# DEBUGSS_WRAP_SECAP_CFG_1_000740002600h register map
Vendor: Texas Instruments
Peripheral module from a debugger description file (folder am62D).
Registers are 32-bit, read-write, reset 0x0 unless marked. A register's access mark holds for its fields unless they carry their own. Offsets are as the file gives them; lines under a group give offsets from that group; [hi:lo] are bit positions; {n}, {i} and the like mark numbered series; 'fields as' and 'values as' point back to an identical list; <NAME> marks a mode.

## secap_cfg_1
0x00 secap_cfg_1_TXDATA — Data value to send to security controller. Apllication specific
  [31:0] TX_DATA_REGISTER
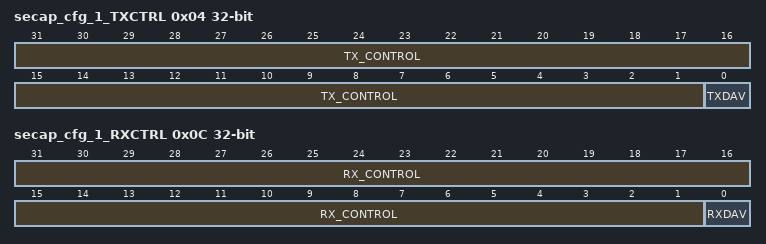
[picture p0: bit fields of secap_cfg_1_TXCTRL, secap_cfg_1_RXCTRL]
0x04 secap_cfg_1_TXCTRL access per field — Register to send control information to the Security Controller, Application specific
  [31:1] TX_CONTROL rw — 31 bits to send to security controller, Application specific
  [0] TXDAV ro — TX Data Available
0x08 secap_cfg_1_RXDATA — Data value from the security controller. Apllication specific
  [31:0] RX_DATA_REGISTER
0x0C secap_cfg_1_RXCTRL ro — Register to receive control information from the Security Controller
  [31:1] RX_CONTROL — 31 bits from the security controller, Application specific
  [0] RXDAV — TX Data Available
